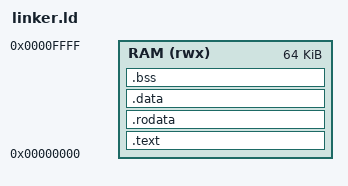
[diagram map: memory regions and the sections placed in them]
/* RV32 user flat memory: link programs for CPU_SIM (64 KiB RAM at 0). */
OUTPUT_ARCH(riscv)
ENTRY(_start)

MEMORY {
  RAM (rwx) : ORIGIN = 0x00000000, LENGTH = 64K
}

SECTIONS {
  .text : {
    *(.text.init)
    *(.text .text.*)
  } > RAM

  .rodata : {
    *(.rodata .rodata.*)
  } > RAM

  .data : {
    *(.data .data.*)
  } > RAM

  .bss : {
    *(.bss .bss.*)
    *(COMMON)
  } > RAM

  PROVIDE(__stack_top = ORIGIN(RAM) + LENGTH(RAM));
}
